# FM33A0XXX register map
File version: 1.0
CPU: SC000 r1p0, little endian, MPU, no FPU, 3 interrupt priority bits
Registers are 32-bit, read-write, reset 0x0 unless marked. A register's access mark holds for its fields unless they carry their own. Offsets are from the block's base; [hi:lo] are bit positions; {n}, {i} and the like mark numbered series; 'fields as' and 'values as' point back to an identical list.

## NVMIF — NVMIF Registers
Base 0x40001000
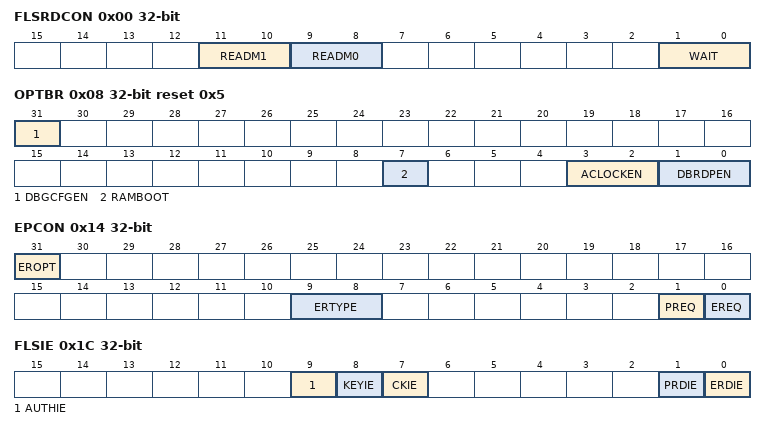
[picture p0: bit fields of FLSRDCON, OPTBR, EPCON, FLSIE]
0x00 FLSRDCON — FLASH read control register
  [11:10] READM1 — ERASE Margin Read
    0=DISABLE (DISABLE Margin Read); 2=ENABLE (ENABLE Margin Read)
  [9:8] READM0 — PROG Margin Read
    values as READM1
  [1:0] WAIT — wait cycle at flash resd
    0=ZERO (0 wait cycle); 1=ONE (1 wait cycle); 2=TWO (2 wait cycle); 3=ZERO (0 wait cycle)
0x04 PRFTCON — PREFATCH CONTROL REGISTER
  [0] PRFTEN — Prefatch Enble
    0=DISABLE (PREFATCH DISABLE); 1=ENABLE (PREFATCH ENABLE)
0x08 OPTBR ro reset 0x5
  [31] DBGCFGEN — DEBUG CONFIG REGISTER ENABLE
    0=DISABLE (DEBUG CONFIG REGISTER DISABLE); 1=ENABLE (DEBUG CONFIG REGISTER ENABLE)
  [7] RAMBOOT
    0=FLASH (FLASH BOOT); 1=RAM (RAM BOOT)
  [3:2] ACLOCKEN
    0=DISABLE (ACLOCK DISABLE); 2=ENABLE (ACLOCK ENABLE)
  [1:0] DBRDPEN — debug port read protect
    0=DISABLE (debug port read protect disable); 2=ENABLE (debug port read protect enable)
0x0C ACLOCK1 — ACLOCK config reister1
0x10 ACLOCK2 — ACLOCK config reister2
0x14 EPCON — erase & prog config register
  [31] EROPT — HOLD CPU AT ERASE AND PROG
  [9:8] ERTYPE — erase tyre
    0=SECTOR (Sector Erase); 1=BLOCK (Block Erase); 2=CHIP (Chip Erase); 3=SECTOR (Sector Erase)
  [1] PREQ wo — Program Request
  [0] EREQ write_only — Erase Request
0x18 FLSKEY — FLASH KEY REGISTER
0x1C FLSIE — FLASH IE
  [9] AUTHIE — AUTH ERR IE
  [8] KEYIE — FLASH KEY ERR IE
  [7] CKIE — CLOCK ERR IE
  [1] PRDIE — PROG FINISH IE
  [0] ERDIE — ERASE FINISH IE
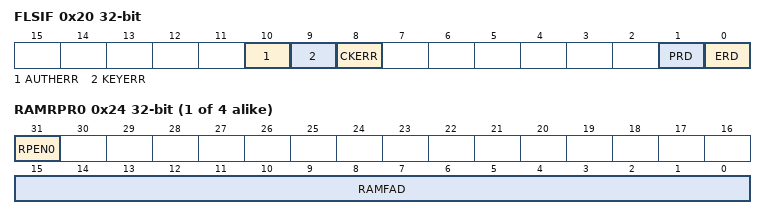
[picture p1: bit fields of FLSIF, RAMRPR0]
0x20 FLSIF — FLASH IF
  [10] AUTHERR — AUTH ERR IF
  [9] KEYERR — KEY ERR IF
  [8] CKERR — CLK ERR IF
  [1] PRD — PROG DONE IF
  [0] ERD — ERASE DONE IF
{0x24+4i} RAMRPR{i} (i=0..3) — RAM Repair Register {i}
  [31] RPEN0 — ram repair enable
    0=DISABLE (RAM repaire disable); 1=ENABLE (RAM repaire enable)
  [15:0] RAMFAD — RAM Repair Addr

## CRC
Base 0x40010000
0x00 CRCDR reset 0xFF — CRC DATA REGISTER
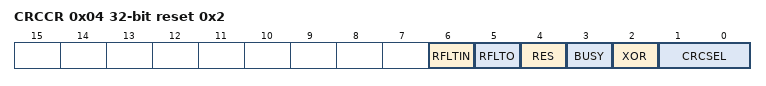
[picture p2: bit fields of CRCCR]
0x04 CRCCR reset 0x2 — CRC CONTROL REGISTER
  [6] RFLTIN — input reverse
  [5] RFLTO — output reverse
  [4] RES ro — result is zero
  [3] BUSY ro
  [2] XOR — OUTPUT XOR
  [1:0] CRCSEL — MODE SELECT
    0=CRC16; 1=CRC8; 2=CCITT; 3=CCITT
0x08 CRCLFSR
  [15:0] LFSR
0x0C CRC_XOR
  [15:0] CRCXOR
0x10 FLSCRCEN — FLASH CRC ENABLE
  [0] FLSCRCEN
0x14 CRCFLSAD — FLASH CRC ADDR
  [16:0] FLSAD
0x18 CRCFLSSIZE — FLASH CRC SIZE
  [16:0] FLSS — SIZE = (FLSS+1)*4

## DISP — DISP Registers
Base 0x40010C00
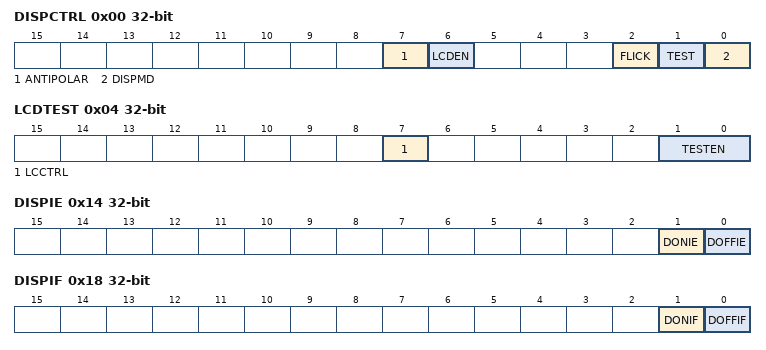
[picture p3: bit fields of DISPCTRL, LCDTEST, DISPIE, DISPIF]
0x00 DISPCTRL — GPIO EXTI Select 0
  [7] ANTIPOLAR — COM & SEG C0ONNECT TO GND OR FLOATING AT DISP DISABLE
    0=FLOATING; 1=GND
  [6] LCDEN — lcd enable
    0=DISABLE; 1=ENABLE
  [2] FLICK — FLICK ENABLE
  [1] TEST — OUTPUT MODE AT TEST
    0=OFF; 1=ON
  [0] DISPMD — DISP MODE
    0=NORMAL (NORMAL MODE); 1=TEST (TEST MODE)
0x04 LCDTEST
  [7] LCCTRL — TEST CONTROL
  [1:0] TESTEN — EXTI1[0] input pin select
0x08 DF — DIVIDED FREQ
  [7:0] DF
0x0C TON — FLICK TIME SETTING
  [7:0] TON
0x10 TOFF — FLICK TIME SETTING
  [7:0] TOFF
0x14 DISPIE
  [1] DONIE — DISPLAY ON IE
  [0] DOFFIE — DISPLAY OFF IE
0x18 DISPIF
  [1] DONIF — DISP ON IF
  [0] DOFFIF — DISP OFF IF
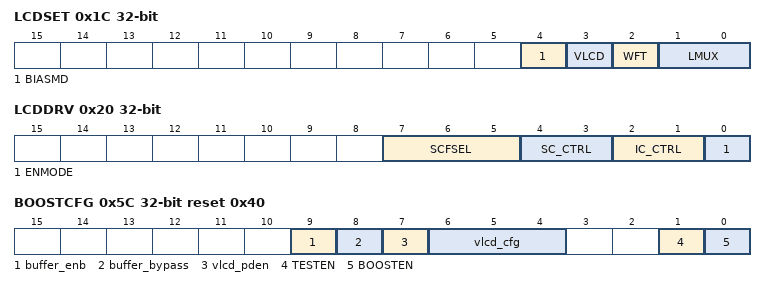
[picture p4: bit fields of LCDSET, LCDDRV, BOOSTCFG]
0x1C LCDSET — LCD SETTING register
  [4] BIASMD — BIAS MODE SELECT
    0=1/4BIAS; 1=1/3BIAS
  [3] VLCD — VLCD SELECT
    0=INNER; 1=OUTER
  [2] WFT — TYPE SELECT
    0=TYPEA (TAPEA); 1=TYPEB
  [1:0] LMUX — COM SELECT
    0=4COM; 1=6COM; 2=8COM; 3=8COM
0x20 LCDDRV — LCD DRIVE SETTING
  [7:5] SCFSEL — SC FREQ SELECT
  [4:3] SC_CTRL — OUTTER CAP DRIVE MODE
  [2:1] IC_CTRL — BIAS CURRENT SEETING
  [0] ENMODE — DRIVE MODE
    0=RBUF (INNER RES BUFF); 1=CAP (OUTTER CAP)
{0x24+4i} DISPDATA{i} (i=0..9) — DISPLAY DATA REGISTER
0x4C LCDBIAS reset 0xE — LCD BIAS SETTING
  [3:0] LCDBIAS
0x50 COM_EN — COM ENABLE
  [3:0] COMEN — COMEN 0-3
0x54 SEG_EN0 — SEG ENABLE
  [31:0] SEGEN
0x58 SEG_EN1 — SEG ENABLE
  [31:0] SEGEN
0x5C BOOSTCFG reset 0x40
  [9] buffer_enb
  [8] buffer_bypass
  [7] vlcd_pden
  [6:4] vlcd_cfg
    0=2.5V; 1=3.0V; 2=3.5V; 3=4.0V; 4=4.5V; 5=5.0V; 6=5.5V; 7=5.5V
  [1] TESTEN
  [0] BOOSTEN
